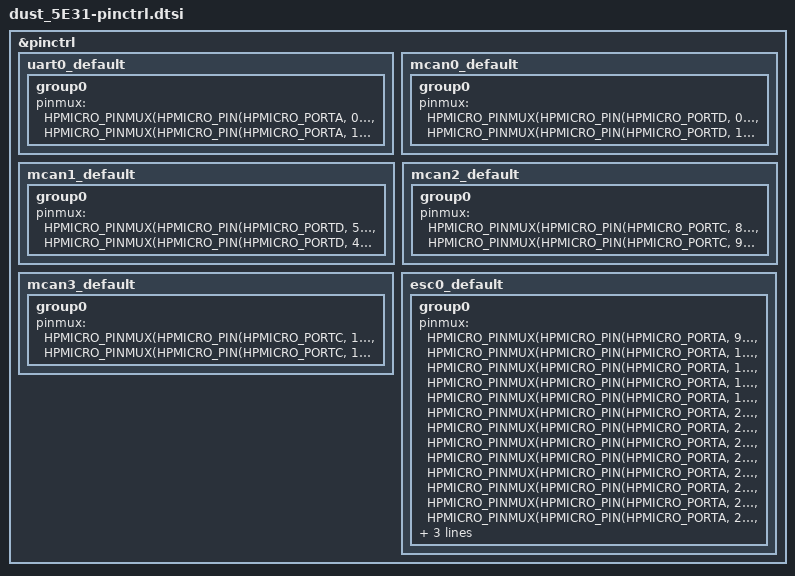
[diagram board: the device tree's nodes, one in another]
/* SPDX-License-Identifier: Apache-2.0 */

#include <dt-bindings/pinctrl/hpmicro-pinctrl-common.h>

&pinctrl {
	uart0_default: uart0_default {
		group0 {
			pinmux = <HPMICRO_PINMUX(HPMICRO_PIN(HPMICRO_PORTA, 0), IOC_TYPE_IOC, 0, 2)>,
				 <HPMICRO_PINMUX(HPMICRO_PIN(HPMICRO_PORTA, 1), IOC_TYPE_IOC, 0, 2)>;
		};
	};

	mcan0_default: mcan0_default {
		group0 {
			/* PD00: MCAN0_TXD, PD01: MCAN0_RXD (IOC ALT7). */
			pinmux = <HPMICRO_PINMUX(HPMICRO_PIN(HPMICRO_PORTD, 0), IOC_TYPE_IOC, 0, 7)>,
				 <HPMICRO_PINMUX(HPMICRO_PIN(HPMICRO_PORTD, 1), IOC_TYPE_IOC, 0, 7)>;
		};
	};

	mcan1_default: mcan1_default {
		group0 {
			/* PD05: MCAN1_TXD, PD04: MCAN1_RXD (IOC ALT7). */
			pinmux = <HPMICRO_PINMUX(HPMICRO_PIN(HPMICRO_PORTD, 5), IOC_TYPE_IOC, 0, 7)>,
				 <HPMICRO_PINMUX(HPMICRO_PIN(HPMICRO_PORTD, 4), IOC_TYPE_IOC, 0, 7)>;
		};
	};

	mcan2_default: mcan2_default {
		group0 {
			/* PC08: MCAN2_TXD, PC09: MCAN2_RXD (IOC ALT7). */
			pinmux = <HPMICRO_PINMUX(HPMICRO_PIN(HPMICRO_PORTC, 8), IOC_TYPE_IOC, 0, 7)>,
				 <HPMICRO_PINMUX(HPMICRO_PIN(HPMICRO_PORTC, 9), IOC_TYPE_IOC, 0, 7)>;
		};
	};

	mcan3_default: mcan3_default {
		group0 {
			/* PC15: MCAN3_TXD, PC14: MCAN3_RXD (IOC ALT7). */
			pinmux = <HPMICRO_PINMUX(HPMICRO_PIN(HPMICRO_PORTC, 15), IOC_TYPE_IOC, 0, 7)>,
				 <HPMICRO_PINMUX(HPMICRO_PIN(HPMICRO_PORTC, 14), IOC_TYPE_IOC, 0, 7)>;
		};
	};

	esc0_default: esc0_default {
		group0 {
			/* REFCK, Port0 MII, MDIO/MDC use IOC ALT11.
			 * PA22 belongs to UART5_RX and is deliberately excluded.
			 */
			pinmux = <HPMICRO_PINMUX(HPMICRO_PIN(HPMICRO_PORTA, 9), IOC_TYPE_IOC, 0, 11)>,
				 <HPMICRO_PINMUX(HPMICRO_PIN(HPMICRO_PORTA, 16), IOC_TYPE_IOC, 0, 11)>,
				 <HPMICRO_PINMUX(HPMICRO_PIN(HPMICRO_PORTA, 17), IOC_TYPE_IOC, 0, 11)>,
				 <HPMICRO_PINMUX(HPMICRO_PIN(HPMICRO_PORTA, 18), IOC_TYPE_IOC, 0, 11)>,
				 <HPMICRO_PINMUX(HPMICRO_PIN(HPMICRO_PORTA, 19), IOC_TYPE_IOC, 0, 11)>,
				 <HPMICRO_PINMUX(HPMICRO_PIN(HPMICRO_PORTA, 20), IOC_TYPE_IOC, 0, 11)>,
				 <HPMICRO_PINMUX(HPMICRO_PIN(HPMICRO_PORTA, 21), IOC_TYPE_IOC, 0, 11)>,
				 <HPMICRO_PINMUX(HPMICRO_PIN(HPMICRO_PORTA, 23), IOC_TYPE_IOC, 0, 11)>,
				 <HPMICRO_PINMUX(HPMICRO_PIN(HPMICRO_PORTA, 24), IOC_TYPE_IOC, 0, 11)>,
				 <HPMICRO_PINMUX(HPMICRO_PIN(HPMICRO_PORTA, 25), IOC_TYPE_IOC, 0, 11)>,
				 <HPMICRO_PINMUX(HPMICRO_PIN(HPMICRO_PORTA, 26), IOC_TYPE_IOC, 0, 11)>,
				 <HPMICRO_PINMUX(HPMICRO_PIN(HPMICRO_PORTA, 27), IOC_TYPE_IOC, 0, 11)>,
				 <HPMICRO_PINMUX(HPMICRO_PIN(HPMICRO_PORTA, 28), IOC_TYPE_IOC, 0, 11)>,
				 <HPMICRO_PINMUX(HPMICRO_PIN(HPMICRO_PORTA, 29), IOC_TYPE_IOC, 0, 11)>,
				 <HPMICRO_PINMUX(HPMICRO_PIN(HPMICRO_PORTA, 30), IOC_TYPE_IOC, 0, 11)>,
				 <HPMICRO_PINMUX(HPMICRO_PIN(HPMICRO_PORTA, 31), IOC_TYPE_IOC, 0, 11)>;
		};
	};
};
